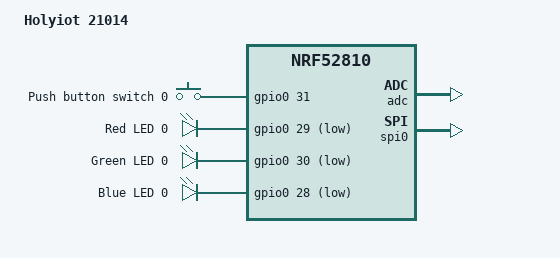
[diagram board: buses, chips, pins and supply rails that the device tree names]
/*
 * SPDX-FileCopyrightText: Copyright (c) 2025 Clunky Machines
 *
 * SPDX-License-Identifier: Apache-2.0
 */

/dts-v1/;
#include <nordic/nrf52810_qfaa.dtsi>
#include "holyiot_21014-pinctrl.dtsi"
#include <zephyr/dt-bindings/input/input-event-codes.h>

/ {
	model = "Holyiot 21014";
	compatible = "holyiot,21014";

	chosen {
		zephyr,sram = &sram0;
		zephyr,flash = &flash0;
		zephyr,code-partition = &slot0_partition;
	};

	buttons {
		compatible = "gpio-keys";

		button0: button_0 {
			gpios = <&gpio0 31 GPIO_ACTIVE_HIGH>;
			label = "Push button switch 0";
			zephyr,code = <INPUT_KEY_0>;
		};
	};

	leds {
		compatible = "gpio-leds";

		led0_red: led_0 {
			gpios = <&gpio0 29 GPIO_ACTIVE_LOW>;
			label = "Red LED 0";
		};

		led0_green: led_1 {
			gpios = <&gpio0 30 GPIO_ACTIVE_LOW>;
			label = "Green LED 0";
		};

		led0_blue: led_2 {
			gpios = <&gpio0 28 GPIO_ACTIVE_LOW>;
			label = "Blue LED 0";
		};
	};

	aliases {
		led0 = &led0_red;
		led1 = &led0_green;
		led2 = &led0_blue;
		led0-red = &led0_red;
		led0-green = &led0_green;
		led0-blue = &led0_blue;
		sw0 = &button0;
		watchdog0 = &wdt0;
	};
};

&reg {
	regulator-initial-mode = <NRF5X_REG_MODE_DCDC>;
};

&adc {
	status = "okay";
};

&gpiote {
	status = "okay";
};

&gpio0 {
	status = "okay";
};

&uicr {
	gpio-as-nreset;
};

&spi0 {
	compatible = "nordic,nrf-spi";
	status = "okay";
	pinctrl-0 = <&spi0_default>;
	pinctrl-1 = <&spi0_sleep>;
	pinctrl-names = "default", "sleep";
};

&flash0 {
	partitions {
		compatible = "fixed-partitions";
		#address-cells = <1>;
		#size-cells = <1>;

		boot_partition: partition@0 {
			label = "mcuboot";
			reg = <0x00000000 0x0000c000>;
		};

		slot0_partition: partition@c000 {
			label = "image-0";
			reg = <0x0000c000 0x0000f000>;
		};

		slot1_partition: partition@1b000 {
			label = "image-1";
			reg = <0x0001b000 0x0000f000>;
		};

		storage_partition: partition@2a000 {
			label = "storage";
			reg = <0x0002a000 0x00006000>;
		};
	};
};
